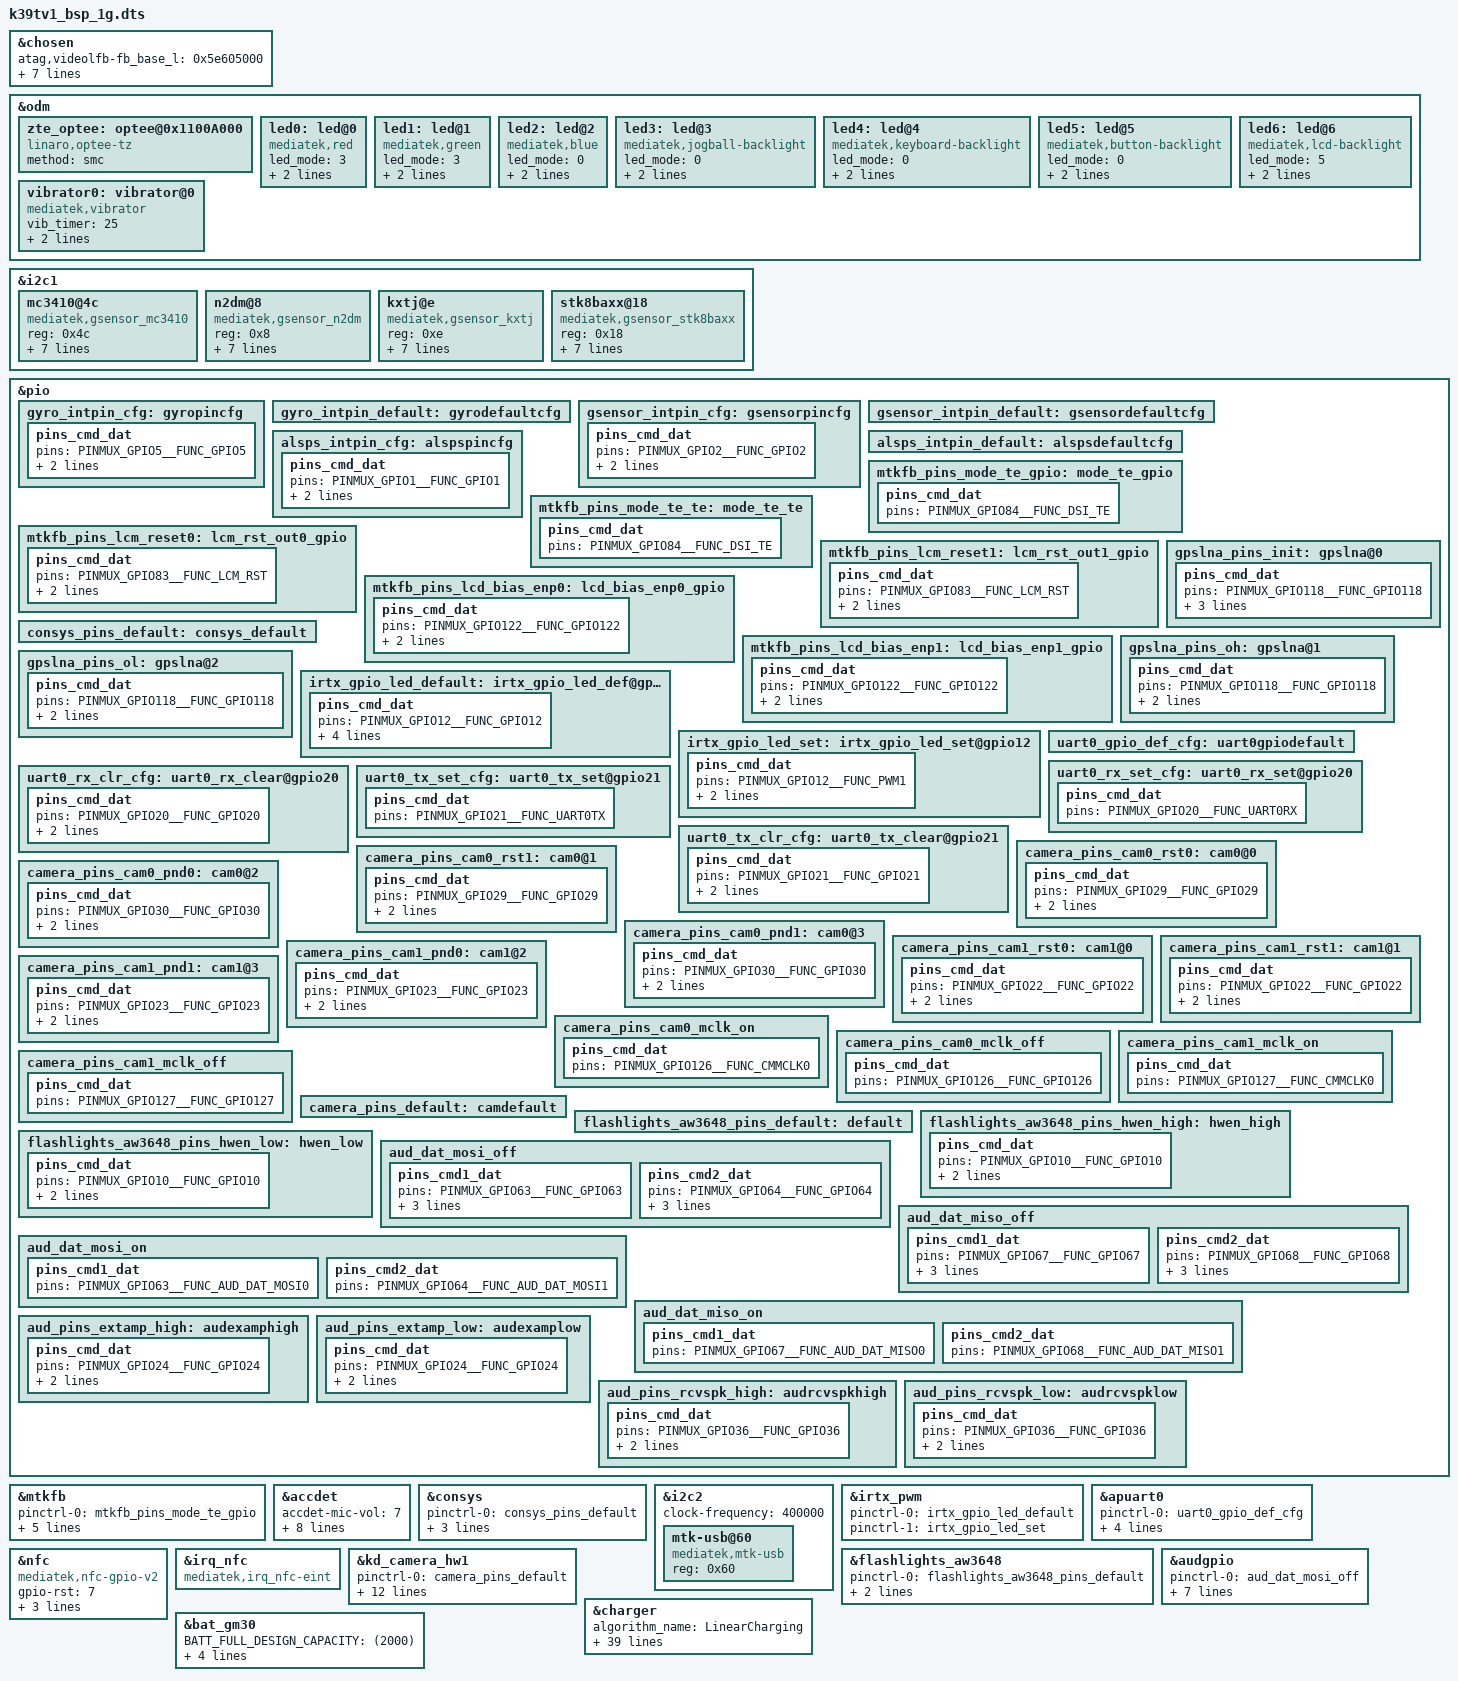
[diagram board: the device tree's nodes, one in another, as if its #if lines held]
#include <generated/autoconf.h>
/dts-v1/;

#ifdef CONFIG_MTK_DTBO_FEATURE
/plugin/;
#include <dt-bindings/mmc/mt6739-msdc.h>
#include <dt-bindings/pinctrl/mt6739-pinfunc.h>
#else
#include "mt6739.dts"
#endif

/* chosen */
&chosen {
	/* fpga may has no lk, we need to specify display info here */
	/* fb buffer is reserved using this dts by memory node above */

	atag,videolfb-fb_base_l = <0x5e605000>;
	atag,videolfb-fb_base_h = <0>;
	atag,videolfb-islcmfound = <1>;
	atag,videolfb-islcm_inited = <0>;
	atag,videolfb-fps= <6000>;
	atag,videolfb-vramSize= <0x017bb000>;
	atag,videolfb-lcmname= "nt35521_hd_dsi_vdo_truly_nt50358_drv";
};

&odm {
	zte_optee: optee@0x1100A000 {
		compatible = "linaro,optee-tz";
		method = "smc";
	};
	led0:led@0 {
		compatible = "mediatek,red";
		led_mode = <3>;
		data = <2>;
		pwm_config = <0 0 0 0 0>;
	};
	led1:led@1 {
		compatible = "mediatek,green";
		led_mode = <3>;
		data = <1>;
		pwm_config = <0 0 0 0 0>;
	};
	led2:led@2 {
		compatible = "mediatek,blue";
		led_mode = <0>;
		data = <1>;
		pwm_config = <0 0 0 0 0>;
	};
	led3:led@3 {
		compatible = "mediatek,jogball-backlight";
		led_mode = <0>;
		data = <1>;
		pwm_config = <0 0 0 0 0>;
	};
	led4:led@4 {
		compatible = "mediatek,keyboard-backlight";
		led_mode = <0>;
		data = <1>;
		pwm_config = <0 0 0 0 0>;
	};
	led5:led@5 {
		compatible = "mediatek,button-backlight";
		led_mode = <0>;
		data = <1>;
		pwm_config = <0 0 0 0 0>;
	};
	led6:led@6 {
		compatible = "mediatek,lcd-backlight";
		led_mode = <5>;
		data = <1>;
		pwm_config = <1 2 0 0 0>;
	};
	vibrator0:vibrator@0 {
		compatible = "mediatek,vibrator";
		vib_timer = <25>;
		vib_limit = <11>;
		vib_vol= <11>;
	};
};

&i2c1 {
/*  start sensor */
	status = "okay";
	mc3410@4c {
		compatible = "mediatek,gsensor_mc3410";
		reg = <0x4c>;
		pinctrl-names = "pin_default", "pin_cfg";
		pinctrl-0 = <&gsensor_intpin_default>;
		pinctrl-1 = <&gsensor_intpin_cfg>;
		direction = <7>;
		power_id = <0xffff>;
		power_vol = <0>;
		firlen = <16>;
		is_batch_supported = <1>;
	};

	n2dm@8 {
		compatible = "mediatek,gsensor_n2dm";
		reg = <0x8>;
		pinctrl-names = "pin_default", "pin_cfg";
		pinctrl-0 = <&gsensor_intpin_default>;
		pinctrl-1 = <&gsensor_intpin_cfg>;
		direction = <7>;
		power_id = <0xffff>;
		power_vol = <0>;
		firlen = <16>;
		is_batch_supported = <1>;
	};
	kxtj@e {
		compatible = "mediatek,gsensor_kxtj";
		reg = <0xe>;
		pinctrl-names = "pin_default", "pin_cfg";
		pinctrl-0 = <&gsensor_intpin_default>;
		pinctrl-1 = <&gsensor_intpin_cfg>;
		direction = <7>;
		power_id = <0xffff>;
		power_vol = <0>;
		firlen = <16>;
		is_batch_supported = <1>;
	};

	stk8baxx@18 {
		compatible = "mediatek,gsensor_stk8baxx";
		reg = <0x18>;
		pinctrl-names = "pin_default", "pin_cfg";
		pinctrl-0 = <&gsensor_intpin_default>;
		pinctrl-1 = <&gsensor_intpin_cfg>;
		direction = <7>;
		power_id = <0xffff>;
		power_vol = <0>;
		firlen = <16>;
		is_batch_supported = <1>;
	};
/* end sensor */
};

/* sensor gpio standization */
&pio {

	gyro_intpin_cfg: gyropincfg {

	    pins_cmd_dat {
			pins = <PINMUX_GPIO5__FUNC_GPIO5>;
			slew-rate = <0>;
			bias-pull-down = <00>;
		};
	};

	gyro_intpin_default: gyrodefaultcfg {
	};
	gsensor_intpin_cfg: gsensorpincfg {
	    pins_cmd_dat {
			pins = <PINMUX_GPIO2__FUNC_GPIO2>;
			slew-rate = <0>;
			bias-pull-down = <00>;
		};
	};
	gsensor_intpin_default: gsensordefaultcfg {
	};
};

&pio {
	alsps_intpin_cfg: alspspincfg {

		pins_cmd_dat {
			pins = <PINMUX_GPIO1__FUNC_GPIO1>;
			slew-rate = <0>;
			bias-pull-up = <MTK_PUPD_SET_R1R0_01>;
		};
	};

	alsps_intpin_default: alspsdefaultcfg {

	};
};

/* sensor end */

/* DISPSYS GPIO standardization */
&pio {
	mtkfb_pins_mode_te_gpio: mode_te_gpio {
		pins_cmd_dat {
			pins = <PINMUX_GPIO84__FUNC_DSI_TE>;
		};
	};

	mtkfb_pins_mode_te_te: mode_te_te {
		pins_cmd_dat {
			pins = <PINMUX_GPIO84__FUNC_DSI_TE>;
		};
	};

	mtkfb_pins_lcm_reset0: lcm_rst_out0_gpio {
		pins_cmd_dat {
			pins = <PINMUX_GPIO83__FUNC_LCM_RST>;
			slew-rate = <1>;
			output-low;
		};
	};

	mtkfb_pins_lcm_reset1: lcm_rst_out1_gpio {
		pins_cmd_dat {
			pins = <PINMUX_GPIO83__FUNC_LCM_RST>;
			slew-rate = <1>;
			output-high;
		};
	};

	mtkfb_pins_lcd_bias_enp0: lcd_bias_enp0_gpio {
		pins_cmd_dat {
			pins = <PINMUX_GPIO122__FUNC_GPIO122>;
			slew-rate = <1>;
			output-low;
		};
	};
	mtkfb_pins_lcd_bias_enp1: lcd_bias_enp1_gpio {
		pins_cmd_dat {
			pins = <PINMUX_GPIO122__FUNC_GPIO122>;
			slew-rate = <1>;
			output-high;
		};
	};

};

&mtkfb {
	pinctrl-names = "mode_te_gpio", "mode_te_te", "lcm_rst_out0_gpio",
		"lcm_rst_out1_gpio", "lcd_bias_enp0_gpio", "lcd_bias_enp1_gpio";
	pinctrl-0 = <&mtkfb_pins_mode_te_gpio>;
	pinctrl-1 = <&mtkfb_pins_mode_te_te>;
	pinctrl-2 = <&mtkfb_pins_lcm_reset0>;
	pinctrl-3 = <&mtkfb_pins_lcm_reset1>;
	pinctrl-4 = <&mtkfb_pins_lcd_bias_enp0>;
	pinctrl-5 = <&mtkfb_pins_lcd_bias_enp1>;
	status = "okay";
};
/* DISPSYS GPIO standardization end */


/* accdet start */
&accdet {
	/* accdet micbias voltage: 0x07,2.7v;0x05,2.5v;0x02,1.9v */
	accdet-mic-vol = <7>;
	headset-mode-setting = <0x500 0x500 1 0x1f0 0x800 0x800 0x20 0x44>;
	accdet-plugout-debounce = <1>;
	/*1:ACC mode, 2:low cost without in bias, 6:low cost with in bias*/
	accdet-mic-mode = <1>;
	/* eint_level_trigger: 8,LEVEL_LOW(default);4,LEVEL_HIGH;others,LEVEL_LOW */
	headset-eint-level-pol = <8>;
	/*0--MD_MAX--UP_MAX--DW_MAX*/
	headset-three-key-threshold = <0 80 220 400>;
	headset-three-key-threshold-CDD = <0 121 192 600>;
	/*0--MD_MAX--VOICE_MAX--UP_MAX--DW_MAX*/
	headset-four-key-threshold = <0 58 121 192 400>;
	status = "okay";
};
/* accdet end */
/* CONSYS GPIO standardization */
&pio {
	consys_pins_default: consys_default {
	};
	gpslna_pins_init: gpslna@0 {
		pins_cmd_dat {
			pins = <PINMUX_GPIO118__FUNC_GPIO118>;
			slew-rate = <0>;
			bias-disable;
			output-low;
		};
	};
	gpslna_pins_oh: gpslna@1 {
		pins_cmd_dat {
			pins = <PINMUX_GPIO118__FUNC_GPIO118>;
			slew-rate = <1>;
			output-high;
		};
	};
	gpslna_pins_ol: gpslna@2 {
		pins_cmd_dat {
			pins = <PINMUX_GPIO118__FUNC_GPIO118>;
			slew-rate = <1>;
			output-low;
		};
	};
};
&consys {
	pinctrl-names = "default", "gps_lna_state_init", "gps_lna_state_oh", "gps_lna_state_ol";
	pinctrl-0 = <&consys_pins_default>;
	pinctrl-1 = <&gpslna_pins_init>;
	pinctrl-2 = <&gpslna_pins_oh>;
	pinctrl-3 = <&gpslna_pins_ol>;
	status = "okay";
};
&i2c2 {
	#address-cells = <1>;
	#size-cells = <0>;
	clock-frequency = <400000>;

	mtk-usb@60 {
		compatible = "mediatek,mtk-usb";
		reg = <0x60>;
		status = "okay";
	};
};

/* IRTX GPIO Start */
&irtx_pwm {
	pinctrl-names = "irtx_gpio_led_default", "irtx_gpio_led_set";
	pinctrl-0 = <&irtx_gpio_led_default>;
	pinctrl-1 = <&irtx_gpio_led_set>;
	status = "okay";
};
&pio {
	/* IRTX GPIO Settings -Start */
	/* default: GPIO0, output, high */
	irtx_gpio_led_default:irtx_gpio_led_def@gpio12 {
		pins_cmd_dat {
			pins = <PINMUX_GPIO12__FUNC_GPIO12>;
			slew-rate = <1>;
			bias-disable;
			output-low;
			input-schmitt-enable = <0>;
		};
	};

	irtx_gpio_led_set:irtx_gpio_led_set@gpio12 {
		pins_cmd_dat {
			pins = <PINMUX_GPIO12__FUNC_PWM1>;
			slew-rate = <1>;
			output-high;
		};
	};
}; /* IRTX GPIO Settings -End */

/* UART GPIO */
&apuart0 {
	pinctrl-names = "uart0_gpio_default",
			"uart0_rx_set",
			"uart0_rx_clear",
			"uart0_tx_set",
			"uart0_tx_clear";
	pinctrl-0 = <&uart0_gpio_def_cfg>;
	pinctrl-1 = <&uart0_rx_set_cfg>;
	pinctrl-2 = <&uart0_rx_clr_cfg>;
	pinctrl-3 = <&uart0_tx_set_cfg>;
	pinctrl-4 = <&uart0_tx_clr_cfg>;
	status = "okay";
};

&pio {
	/* UART GPIO Settings - Start */
	/* UART0: rx set, rx clear, tx clear, tx clear*/
	uart0_gpio_def_cfg:uart0gpiodefault {

	};
	uart0_rx_set_cfg:uart0_rx_set@gpio20 {
		pins_cmd_dat {
			pins = <PINMUX_GPIO20__FUNC_UART0RX>;
		};
	};
	uart0_rx_clr_cfg:uart0_rx_clear@gpio20 {
		pins_cmd_dat {
			pins = <PINMUX_GPIO20__FUNC_GPIO20>;
			slew-rate = <1>;
			output-high;
		};
	};
	uart0_tx_set_cfg:uart0_tx_set@gpio21 {
		pins_cmd_dat {
			pins = <PINMUX_GPIO21__FUNC_UART0TX>;
		};
	};
	uart0_tx_clr_cfg:uart0_tx_clear@gpio21 {
		pins_cmd_dat {
			pins = <PINMUX_GPIO21__FUNC_GPIO21>;
			slew-rate = <1>;
			output-high;
		};
	};
};/* UART GPIO end */

/* NFC start */
&nfc {
	compatible = "mediatek,nfc-gpio-v2";
	gpio-rst = <7>;
	gpio-rst-std = <&pio 7 0x0>;
	gpio-irq = <14>;
	gpio-irq-std = <&pio 14 0x0>;
};

&irq_nfc {
	compatible = "mediatek,irq_nfc-eint";
};
/* NFC end */

/* CAMERA GPIO standardization */
&pio {
	camera_pins_cam0_rst0: cam0@0 {
		pins_cmd_dat {
			pins = <PINMUX_GPIO29__FUNC_GPIO29>;
			slew-rate = <1>; /*direction 0:in, 1:out*/
			output-low;/*direction out used only. output_low or high*/
		};
	};
	camera_pins_cam0_rst1: cam0@1 {
		pins_cmd_dat {
			pins = <PINMUX_GPIO29__FUNC_GPIO29>;
			slew-rate = <1>;
			output-high;
		};
	};
	camera_pins_cam0_pnd0: cam0@2 {
		pins_cmd_dat {
			pins = <PINMUX_GPIO30__FUNC_GPIO30>;
			slew-rate = <1>;
			output-low;
		};
	};
	camera_pins_cam0_pnd1: cam0@3 {
		pins_cmd_dat {
			pins = <PINMUX_GPIO30__FUNC_GPIO30>;
			slew-rate = <1>;
			output-high;
		};
	};
	camera_pins_cam1_rst0: cam1@0 {
		pins_cmd_dat {
			pins = <PINMUX_GPIO22__FUNC_GPIO22>;
			slew-rate = <1>; /*direction 0:in, 1:out*/
			output-low;/*direction out used only. output_low or high*/
		};
	};
	camera_pins_cam1_rst1: cam1@1 {
		pins_cmd_dat {
			pins = <PINMUX_GPIO22__FUNC_GPIO22>;
			slew-rate = <1>;
			output-high;
		};
	};
	camera_pins_cam1_pnd0: cam1@2 {
		pins_cmd_dat {
			pins = <PINMUX_GPIO23__FUNC_GPIO23>;
			slew-rate = <1>;
			output-low;
		};
	};
	camera_pins_cam1_pnd1: cam1@3 {
		pins_cmd_dat {
			pins = <PINMUX_GPIO23__FUNC_GPIO23>;
			slew-rate = <1>;
			output-high;
		};
	};
	/*camera_pins_cam_ldo_sub_vcamd_0: cam1@vcamd0 {
		pins_cmd_dat {
			pins = <PINMUX_GPIO9__FUNC_GPIO9>;
			slew-rate = <1>;
			output-low;
		};
	};
	camera_pins_cam_ldo_sub_vcamd_1: cam1@vcamd1 {
		pins_cmd_dat {
			pins = <PINMUX_GPIO9__FUNC_GPIO9>;
			slew-rate = <1>;
			output-high;
		};
	};*/
	camera_pins_cam0_mclk_on: camera_pins_cam0_mclk_on {
		pins_cmd_dat {
			pins = <PINMUX_GPIO126__FUNC_CMMCLK0>;
		};
	};
	camera_pins_cam0_mclk_off: camera_pins_cam0_mclk_off {
		pins_cmd_dat {
			pins = <PINMUX_GPIO126__FUNC_GPIO126>;
		};
	};
	camera_pins_cam1_mclk_on: camera_pins_cam1_mclk_on {
		pins_cmd_dat {
			pins = <PINMUX_GPIO127__FUNC_CMMCLK0>;
		};
	};
	camera_pins_cam1_mclk_off: camera_pins_cam1_mclk_off {
		pins_cmd_dat {
			pins = <PINMUX_GPIO127__FUNC_GPIO127>;
		};
	};
	camera_pins_default: camdefault {
	};
};

&kd_camera_hw1 {
	pinctrl-names = "default",
			"cam0_rst0", "cam0_rst1", "cam0_pnd0", "cam0_pnd1",
			"cam1_rst0", "cam1_rst1", "cam1_pnd0", "cam1_pnd1",
			"cam0_mclk_on", "cam0_mclk_off",
			"cam1_mclk_on", "cam1_mclk_off";
			/*"cam_ldo_sub_vcamd_0", "cam_ldo_sub_vcamd_1",*/

	pinctrl-0 = <&camera_pins_default>;
	pinctrl-1 = <&camera_pins_cam0_rst0>;
	pinctrl-2 = <&camera_pins_cam0_rst1>;
	pinctrl-3 = <&camera_pins_cam0_pnd0>;
	pinctrl-4 = <&camera_pins_cam0_pnd1>;
	pinctrl-5 = <&camera_pins_cam1_rst0>;
	pinctrl-6 = <&camera_pins_cam1_rst1>;
	pinctrl-7 = <&camera_pins_cam1_pnd0>;
	pinctrl-8 = <&camera_pins_cam1_pnd1>;
	pinctrl-9 = <&camera_pins_cam0_mclk_on>;
	pinctrl-10 = <&camera_pins_cam0_mclk_off>;
	pinctrl-11 = <&camera_pins_cam1_mclk_on>;
	pinctrl-12 = <&camera_pins_cam1_mclk_off>;
	status = "okay";
};
/* CAMERA GPIO end */

/*Flashlight GPIO begin*/
&pio {
	flashlights_aw3648_pins_default:default {
	};
	flashlights_aw3648_pins_hwen_high:hwen_high {
		pins_cmd_dat {
			pins = <PINMUX_GPIO10__FUNC_GPIO10>;
			slew-rate = <1>;
			output-high;
		};
	};
	flashlights_aw3648_pins_hwen_low:hwen_low {
		pins_cmd_dat {
			pins = <PINMUX_GPIO10__FUNC_GPIO10>;
			slew-rate = <1>;
			output-low;
		};
	};
};

&flashlights_aw3648 {
	pinctrl-names = "default", "hwen_high", "hwen_low";
	pinctrl-0 = <&flashlights_aw3648_pins_default>;
	pinctrl-1 = <&flashlights_aw3648_pins_hwen_high>;
	pinctrl-2 = <&flashlights_aw3648_pins_hwen_low>;
	status = "okay";
};

/*Flashlight GPIO end*/

/* AUDIO GPIO standardization */
&audgpio {
	pinctrl-names = "aud_dat_mosi_off",
			"aud_dat_mosi_on",
			"aud_dat_miso_off",
			"aud_dat_miso_on",
			"extamp-pullhigh",
			"extamp-pulllow",
			"rcvspk-pullhigh",
			"rcvspk-pulllow";
	pinctrl-0 = <&aud_dat_mosi_off>;
	pinctrl-1 = <&aud_dat_mosi_on>;
	pinctrl-2 = <&aud_dat_miso_off>;
	pinctrl-3 = <&aud_dat_miso_on>;
	pinctrl-4 = <&aud_pins_extamp_high>;
	pinctrl-5 = <&aud_pins_extamp_low>;
	pinctrl-6 = <&aud_pins_rcvspk_high>;
	pinctrl-7 = <&aud_pins_rcvspk_low>;
	status = "okay";
};

&pio {
	aud_dat_mosi_off: aud_dat_mosi_off {
		pins_cmd1_dat {
			pins = <PINMUX_GPIO63__FUNC_GPIO63>;
			input-enable;
			slew-rate = <0>;
			bias-disable;
		};
		pins_cmd2_dat {
			pins = <PINMUX_GPIO64__FUNC_GPIO64>;
			input-enable;
			slew-rate = <0>;
			bias-disable;
		};
	};

	aud_dat_mosi_on: aud_dat_mosi_on {
		pins_cmd1_dat {
			pins = <PINMUX_GPIO63__FUNC_AUD_DAT_MOSI0>;
		};
		pins_cmd2_dat {
			pins = <PINMUX_GPIO64__FUNC_AUD_DAT_MOSI1>;
		};
	};

	aud_dat_miso_off: aud_dat_miso_off {
		pins_cmd1_dat {
			pins = <PINMUX_GPIO67__FUNC_GPIO67>;
			input-enable;
			slew-rate = <0>;
			bias-disable;
		};
		pins_cmd2_dat {
			pins = <PINMUX_GPIO68__FUNC_GPIO68>;
			input-enable;
			slew-rate = <0>;
			bias-disable;
		};
	};

	aud_dat_miso_on: aud_dat_miso_on {
		pins_cmd1_dat {
			pins = <PINMUX_GPIO67__FUNC_AUD_DAT_MISO0>;
		};
		pins_cmd2_dat {
			pins = <PINMUX_GPIO68__FUNC_AUD_DAT_MISO1>;
		};
	};
	aud_pins_extamp_high: audexamphigh {
		pins_cmd_dat {
			pins = <PINMUX_GPIO24__FUNC_GPIO24>;
			slew-rate = <1>;
			output-high;
		};
	};

	aud_pins_extamp_low: audexamplow {
		pins_cmd_dat {
			pins = <PINMUX_GPIO24__FUNC_GPIO24>;
			slew-rate = <1>;
			output-low;
		};
	};
	aud_pins_rcvspk_high: audrcvspkhigh {
		pins_cmd_dat {
			pins = <PINMUX_GPIO36__FUNC_GPIO36>;
			slew-rate = <1>;
			output-high;
		};
	};

	aud_pins_rcvspk_low: audrcvspklow {
		pins_cmd_dat {
			pins = <PINMUX_GPIO36__FUNC_GPIO36>;
			slew-rate = <1>;
			output-low;
		};
	};

};
/* AUDIO end */

&charger {
	algorithm_name = "LinearCharging";
	enable_sw_jeita;
	battery_cv = <4350000>;
	max_charger_voltage = <6000000>;
	ac_charger_input_current = <800000>;
	ac_charger_current = <800000>;
	charging_host_charger_current = <800000>;
	ta_ac_charger_current = <800000>;

	/* sw jeita */
	jeita_temp_above_t4_cv_voltage = <4100000>;
	jeita_temp_t3_to_t4_cv_voltage = <4100000>;
	jeita_temp_t2_to_t3_cv_voltage = <4350000>;
	jeita_temp_t1_to_t2_cv_voltage = <4350000>;
	jeita_temp_t0_to_t1_cv_voltage = <4350000>;
	jeita_temp_below_t0_cv_voltage = <4100000>;

	jeita_temp_above_t4_chg_current = <0>;
	jeita_temp_t3_to_t4_chg_current = <600000>;
	jeita_temp_t2_to_t3_chg_current = <800000>;
	jeita_temp_t1_to_t2_chg_current = <600000>;
	jeita_temp_t0_to_t1_chg_current = <600000>;
	jeita_temp_below_t0_chg_current = <0>;

	temp_t4_threshold = <55>;
	temp_t4_thres_minus_x_degree = <52>;
	temp_t3_threshold = <45>;
	temp_t3_thres_minus_x_degree = <42>;
	temp_t2_threshold = <15>;
	temp_t2_thres_plus_x_degree = <18>;
	temp_t1_threshold = <5>;
	temp_t1_thres_plus_x_degree = <8>;
	temp_t0_threshold = <0>;
	temp_t0_thres_plus_x_degree = <3>;
	temp_neg_10_threshold = <0>;

	/* battery temperature protection */
	enable_min_charge_temperature;
	min_charge_temperature = <0>;
	min_charge_temperature_plus_x_degree = <3>;
	max_charge_temperature = <55>;
	max_charge_temperature_minus_x_degree = <52>;

	max_charging_time = <72000>; /* 20 hours */
	/* linear charger */
	recharge_offset = <100000>;
	topoff_voltage = <4200000>;
	chg_full_current = <150000>;
};

&bat_gm30 {
	BATT_FULL_DESIGN_CAPACITY = <(2000)>;
	SHUTDOWN_1_TIME = <(10)>;
	R_FG_VALUE = <(10)>;
	EMBEDDED_SEL = <(1)>;
	CAR_TUNE_VALUE = <(102)>;

	#include "../bat_setting/mt6739_battery_table_ext_2000mah_Z3351S.dtsi"
};

#include <k39tv1_bsp_1g_salable/cust.dtsi>
#include  "touchscreen_salable.dtsi"
/*End of this file, DO NOT ADD ANYTHING HERE*/
